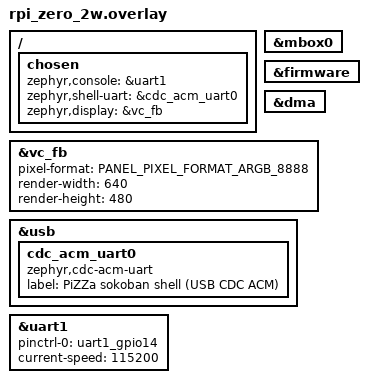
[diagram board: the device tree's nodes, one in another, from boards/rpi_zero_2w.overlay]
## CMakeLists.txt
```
# SPDX-License-Identifier: Apache-2.0
#
# PiZZa -- sokoban (howprice/sdl2-sokoban) via the shared SDL2 shim
# (apps/lib/sdl2shim).
#
# First consumer of the shim's SDL_Renderer engine + TTF-atlas + PIMG
# groups: the game is written against the renderer API proper (unlike
# Doom/SDLPoP/minivmac's app-side composition), so the lib owns the
# whole draw path and this app supplies only the diverging half --
# the baked asset pack + fd layer, the TMX loader over baked records,
# the present backend, the `sok` shell and the scripted timeline.
#
# The game tree is VENDORED at game/ (upstream is dormant; see
# game/PROVENANCE.md for the commit + local patches). MIT game, Apache
# shim/port glue.
#
# C++: the game is C++14-compatible C++; the proven aarch64 recipe is
# CONFIG_CPP + CONFIG_GLIBCXX_LIBCPP in prj.conf plus
# -DTOOLCHAIN_HAS_GLIBCXX=ON on the west line.

cmake_minimum_required(VERSION 3.20.0)

find_package(Zephyr REQUIRED HINTS $ENV{ZEPHYR_BASE})
project(pizza_sokoban LANGUAGES C CXX)

# sample_usbd helper for the USB CDC ACM shell, same as PizzaShell /
# Jet / wipeout / Doom / SDLPoP.
if(CONFIG_USB_DEVICE_STACK_NEXT)
  include(${ZEPHYR_BASE}/samples/subsys/usb/common/common.cmake)
endif()

set(SOK_GAME_DIR ${CMAKE_CURRENT_SOURCE_DIR}/game)

set(SOK_GAME_SRC
  ${SOK_GAME_DIR}/src/main.cpp
  ${SOK_GAME_DIR}/src/App.cpp
  ${SOK_GAME_DIR}/src/Game.cpp
  ${SOK_GAME_DIR}/src/MapRender.cpp
  ${SOK_GAME_DIR}/src/Renderer.cpp
  ${SOK_GAME_DIR}/src/TileMap.cpp
  ${SOK_GAME_DIR}/src/hp_assert.cpp
)

# ── shared shim (apps/lib/sdl2shim) ─────────────────────────────────
include(${CMAKE_CURRENT_SOURCE_DIR}/../lib/sdl2shim/sdl2shim.cmake)

set(SOK_SHIM_SRC
  src/shim_main.c
  src/shim_tmx.c
  src/sok_assets.c
  src/sok_pack.S
  ${SDL2SHIM_CORE_SOURCES}
  ${SDL2SHIM_SURFACE_SOURCES}
  ${SDL2SHIM_RW_SOURCES}
  ${SDL2SHIM_RENDER_SOURCES}
  ${SDL2SHIM_TTF_ATLAS_SOURCES}
  ${SDL2SHIM_IMAGE_PIMG_SOURCES}
)

# Audio backend (lib-owned): sokoban makes no audio calls at all, but
# the core's shim_stub.c delegates to the s2s_audio_* seam, so a
# backend TU must link. NONE stays correct even if a future game
# variant opens audio.
if(CONFIG_SDL2SHIM_AUDIO_HDMI)
  list(APPEND SOK_SHIM_SRC ${SDL2SHIM_AUDIO_HDMI_SOURCES})
else()
  list(APPEND SOK_SHIM_SRC ${SDL2SHIM_AUDIO_NONE})
endif()

# `sok` shell command set -- interactive key injection over USB CDC ACM.
if(CONFIG_SHELL)
  list(APPEND SOK_SHIM_SRC src/shim_shell.c)
endif()

# USB device stack bring-up (lib).
if(CONFIG_USB_DEVICE_STACK_NEXT)
  list(APPEND SOK_SHIM_SRC ${SDL2SHIM_USB})
endif()

# Frame present backend (app-local, as for every shim consumer).
if(CONFIG_SOKOBAN_PRESENT_DISPLAY)
  list(APPEND SOK_SHIM_SRC src/sok_present_display.c)
elseif(CONFIG_SOKOBAN_PRESENT_SEMIHOST)
  list(APPEND SOK_SHIM_SRC src/sok_present_semihost.c)
else()
  list(APPEND SOK_SHIM_SRC src/sok_present_none.c)
endif()

# Scripted synthetic input -- sokoban's title -> level 1 -> moves
# timeline for the qemu sim gate.
if(CONFIG_SOKOBAN_SCRIPTED_INPUT)
  list(APPEND SOK_SHIM_SRC src/shim_scripted.c)
endif()

# BT HID input (pad/keyboard/mouse) via apps/lib/btinput -- rpi_zero_2w
# only (boards/rpi_zero_2w.conf sets CONFIG_BTINPUT; qemu has no radio).
if(CONFIG_BTINPUT)
  include(${CMAKE_CURRENT_SOURCE_DIR}/../lib/btinput/btinput.cmake)
  # The BT patchram (.hcd) is a gitignored vendor blob (PROVENANCE.md).
  # Fail LOUDLY if missing: an empty-patchram image wedges the controller
  # at runtime (Download_Minidriver with nothing to launch).
  if(NOT CONFIG_AIROC_CUSTOM_FIRMWARE_HCD_BLOB)
    message(FATAL_ERROR
      "sokoban+BTINPUT: CONFIG_AIROC_CUSTOM_FIRMWARE_HCD_BLOB is unset")
  endif()
  set(_bt_blob "${CONFIG_AIROC_CUSTOM_FIRMWARE_HCD_BLOB}")
  if(NOT IS_ABSOLUTE "${_bt_blob}")
    set(_bt_blob "${CMAKE_CURRENT_SOURCE_DIR}/${_bt_blob}")
  endif()
  if(NOT EXISTS "${_bt_blob}")
    message(FATAL_ERROR
      "sokoban+BTINPUT: BT patchram not found:\n  ${_bt_blob}\n"
      "It is gitignored (vendor blob) -- fetch it per "
      "apps/lib/btinput/firmware/PROVENANCE.md before building.")
  endif()
  target_sources(app PRIVATE ${BTINPUT_SOURCES} src/sokoban_btinput.c)
  target_include_directories(app PRIVATE ${BTINPUT_INCLUDE_DIRS})
endif()

# Embedded asset pack: pack_assets.py bakes PNG -> PIMG, TMX -> S2TM
# and the ARCADE_N 8 px glyph atlas into one binary, linked via .incbin.
set(SOK_PACK_BIN ${CMAKE_BINARY_DIR}/sokoban_assets.bin)
file(GLOB_RECURSE SOK_DATA_FILES ${SOK_GAME_DIR}/data/*)
add_custom_command(
  OUTPUT ${SOK_PACK_BIN}
  COMMAND ${Python3_EXECUTABLE} ${CMAKE_CURRENT_SOURCE_DIR}/tools/pack_assets.py
          ${SOK_GAME_DIR}/data ${SOK_PACK_BIN} --font "Font/ARCADE_N.TTF@8"
  DEPENDS ${SOK_DATA_FILES}
          ${CMAKE_CURRENT_SOURCE_DIR}/tools/pack_assets.py
  COMMENT "Packing sokoban assets (PNG -> PIMG, TMX -> S2TM, TTF -> S2SA)"
)
add_custom_target(sok_assets_pack DEPENDS ${SOK_PACK_BIN})
add_dependencies(app sok_assets_pack)
set_source_files_properties(src/sok_pack.S PROPERTIES
  OBJECT_DEPENDS ${SOK_PACK_BIN}
  COMPILE_OPTIONS "-I${CMAKE_BINARY_DIR};-Wa,-I${CMAKE_BINARY_DIR}"
)

target_sources(app PRIVATE
  ${SOK_GAME_SRC}
  ${SOK_SHIM_SRC}
)

# include/ order: the shim's include/ first so <SDL2/SDL.h> resolves
# there; the game includes "SDL.h"/"SDL_ttf.h"/"tmx.h" unqualified, so
# the shim's SDL2/ subdir and this app's include/ (tmx.h) are on the
# path directly.
target_include_directories(app PRIVATE
  ${SDL2SHIM_INCLUDE_DIRS}
  ${SDL2SHIM_DIR}/include/SDL2
  include
  src
)

# The vendored game trips warnings its desktop builds silence.
set_source_files_properties(${SOK_GAME_SRC} PROPERTIES COMPILE_OPTIONS
  "-Wno-unused-variable;-Wno-unused-but-set-variable;-Wno-unused-parameter;-Wno-missing-field-initializers;-Wno-format-truncation;-Wno-double-promotion"
)
```

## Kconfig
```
# SPDX-License-Identifier: Apache-2.0
#
# PiZZa sokoban port -- app options.

# SAMPLE_USBD_* options for sample_usbd_init.c on boards with the USB
# device stack. Same pattern PizzaShell / Jet / wipeout / SDLPoP use.
source "samples/subsys/usb/common/Kconfig.sample_usbd"

# Shared shim: the audio-backend choice (NONE default -- sokoban makes
# no audio calls) and the SDL2SHIM log module live here.
rsource "../lib/sdl2shim/Kconfig"
# BT HID input (pad/keyboard/mouse) -- enabled per-board (rpi_zero_2w).
rsource "../lib/btinput/Kconfig"

menu "PiZZa sokoban port"

choice SOKOBAN_PRESENT_BACKEND
	prompt "Frame present backend"
	default SOKOBAN_PRESENT_DISPLAY if DISPLAY
	default SOKOBAN_PRESENT_NONE

config SOKOBAN_PRESENT_DISPLAY
	bool "Zephyr display API (bcm2835_fb + HVS scaling on hardware)"
	depends on DISPLAY

config SOKOBAN_PRESENT_NONE
	bool "Drop frames (link/sim bring-up)"

config SOKOBAN_PRESENT_SEMIHOST
	bool "Semihosting PPM capture (qemu sim gates)"
	depends on SEMIHOST

endchoice

config SOKOBAN_CAPTURE_EVERY
	int "Capture every Nth presented frame (0 = first frame only)"
	depends on SOKOBAN_PRESENT_SEMIHOST
	default 0

config SOKOBAN_SCRIPTED_INPUT
	bool "Drive the game from the scripted synthetic input timeline"
	default n

module = SOKOBAN
module-str = sokoban
source "subsys/logging/Kconfig.template.log_config"

endmenu

source "Kconfig.zephyr"
```

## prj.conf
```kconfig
# SPDX-License-Identifier: Apache-2.0
#
# Common config for the PiZZa sokoban port. Per-board overrides
# (display, USB, semihost capture) live in boards/<board>.conf.

CONFIG_PRINTK=y
CONFIG_BOOT_BANNER=y

# Keep printk() synchronous so boot-time logging lands on the console
# even when the render loop is busy (Jet/wipeout pattern).
CONFIG_LOG_PRINTK=n

# picolibc's errno needs TLS -- same hard-won stanza as the wipeout /
# SDLPoP ports.
CONFIG_TOOLCHAIN_CROSS_COMPILE_SUPPORTS_THREAD_LOCAL_STORAGE=y
CONFIG_THREAD_LOCAL_STORAGE=y

# C++ game sources: the proven aarch64 recipe (real libstdc++ from the
# SDK; needs -DTOOLCHAIN_HAS_GLIBCXX=ON on the west line). No
# exceptions/RTTI -- the game uses neither.
CONFIG_CPP=y
CONFIG_STD_CPP17=y
CONFIG_GLIBCXX_LIBCPP=y

# Heap: the renderer's 640x480 ARGB backing (1.2 MB), the per-level
# map texture (level maps up to ~720x468 -> ~1.4 MB), tileset texture
# + text surfaces, and the ~2.3 MB Game object (new'd). 8 MiB is
# generous headroom.
CONFIG_COMMON_LIBC_MALLOC_ARENA_SIZE=8388608

# The game runs on the Zephyr main thread.
CONFIG_MAIN_STACK_SIZE=65536

CONFIG_FPU=y
CONFIG_STACK_SENTINEL=y
CONFIG_ASSERT=y

# Audio: sokoban makes no SDL audio / Mix_* calls at all; the shim's
# AUDIO_NONE backend (Kconfig default) is the correct choice on every
# board -- do not wire the HDMI backend "for symmetry".
```

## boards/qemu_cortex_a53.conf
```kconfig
# SPDX-License-Identifier: Apache-2.0
#
# qemu_cortex_a53 -- the SIM target. No display hardware: frames leave
# the guest as PPM files via semihosting (sok_present_semihost.c); the
# scripted timeline drives title -> level 1 -> UP/LEFT/LEFT.

# Run the emulated CPU at wall speed (same rationale as SDLPoP: the
# default -icount stretches software rendering ~40x in wall-clock).
CONFIG_QEMU_ICOUNT=n

CONFIG_SEMIHOST=y
CONFIG_SOKOBAN_PRESENT_SEMIHOST=y
CONFIG_SOKOBAN_CAPTURE_EVERY=40
CONFIG_SOKOBAN_SCRIPTED_INPUT=y

# Synchronous shim logging on the emulated console.
CONFIG_LOG=y
CONFIG_LOG_MODE_MINIMAL=y
CONFIG_SOKOBAN_LOG_LEVEL_DBG=y
```

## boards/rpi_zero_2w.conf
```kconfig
# SPDX-License-Identifier: Apache-2.0
#
# Raspberry Pi Zero 2 W (BCM2710, Cortex-A53, AArch64) -- sokoban.
# Console + logs on the mini-UART, interactive shell (`sok key ...`)
# on USB CDC ACM, HDMI via the VC firmware framebuffer with HVS
# 640x480 scaling. No audio (the game makes no audio calls).

CONFIG_BOOT_DELAY=200

# VC mailbox + firmware (framebuffer alloc chain).
CONFIG_RASPBERRYPI_FIRMWARE=y

# HDMI display via VC firmware FB, ARGB_8888. The renderer's 640x480
# frame lands in the virtual FB; HVS scales to the monitor's native
# mode.
CONFIG_DISPLAY=y
CONFIG_BCM2835_FB=y

# BCM2835 DMA -- FB driver claims a channel for the backbuffer blit.
CONFIG_DMA=y
CONFIG_DMA_BCM2835=y

# USB CDC ACM shell, same shape as PizzaShell / wipeout / SDLPoP.
CONFIG_USB_DEVICE_STACK_NEXT=y
CONFIG_UDC_DWC2=y
CONFIG_UDC_DWC2_DMA=n
CONFIG_SERIAL=y
CONFIG_USBD_CDC_ACM_CLASS=y
CONFIG_CDC_ACM_SERIAL_INITIALIZE_AT_BOOT=n
CONFIG_SAMPLE_USBD_PRODUCT="PiZZa sokoban -- rpi_zero_2w"
CONFIG_SAMPLE_USBD_MANUFACTURER="jetpax/PiZZa"
CONFIG_SAMPLE_USBD_PID=0xCAFE
CONFIG_USBD_THREAD_STACK_SIZE=4096
CONFIG_UDC_DWC2_STACK_SIZE=4096

CONFIG_SHELL=y
CONFIG_SHELL_BACKEND_SERIAL=y
CONFIG_KERNEL_SHELL=y
CONFIG_SHELL_STACK_SIZE=8192
CONFIG_SHELL_VT100_COMMANDS=y
CONFIG_SHELL_HISTORY=y
CONFIG_SHELL_TAB=y
CONFIG_SHELL_LOG_BACKEND=n

# Logging on the board console (mini-UART), off the shell prompt.
CONFIG_LOG=y
CONFIG_LOG_BUFFER_SIZE=16384
CONFIG_LOG_BACKEND_UART=y
CONFIG_LOG_MODE_DEFERRED=y
CONFIG_USBD_CDC_ACM_LOG_LEVEL_WRN=y
CONFIG_USBD_LOG_LEVEL_INF=y
CONFIG_UDC_DRIVER_LOG_LEVEL_WRN=y

# ── Bluetooth HID input (8BitDo pad -> sokoban keys) ─────────────────
# Stack, host profile and connection policy all live in apps/lib/btinput;
# config mirrors the HW-proven minivmac/DOSBox bring-up. The pad keymap
# (K-mode letters -> arrows/O/M/R/U/space) is in sokoban_btinput.c.
CONFIG_BTINPUT=y
CONFIG_BTINPUT_HOGP=y
CONFIG_BTINPUT_SEAM_SDL=y
CONFIG_BTINPUT_MANAGER=y

CONFIG_BT=y
CONFIG_BT_CLASSIC=y
CONFIG_BT_DEVICE_NAME="PiZZa"
CONFIG_BT_MAX_PAIRED=8
CONFIG_BT_MAX_CONN=3
# The 8BitDo's fw is legacy-only SMP; Just Works is the accepted trust model.
CONFIG_BT_SMP_SC_PAIR_ONLY=n
# The 4.2 controller has 1M PHY only; skip the doomed LE Set PHY attempt.
CONFIG_BT_AUTO_PHY_UPDATE=n

# Infineon AIROC patchram: this unit is the Synaptics 43436S module
# (BT ROM = 43430A1). Blob is gitignored; PROVENANCE.md has the fetch.
CONFIG_BT_AIROC=y
CONFIG_BT_AIROC_CUSTOM=y
CONFIG_AIROC_CUSTOM_FIRMWARE_HCD_BLOB="../lib/btinput/firmware/SYN43430A1.hcd"

# Bond persistence: settings FILE backend on the SD FAT (the manager
# mounts /SD:). MKFS stays off -- the card is PiZZa-imaged.
CONFIG_BT_SETTINGS=y
CONFIG_SETTINGS=y
CONFIG_SETTINGS_FILE=y
CONFIG_SETTINGS_FILE_PATH="/SD:/bt/settings"
CONFIG_DISK_ACCESS=y
CONFIG_DISK_DRIVERS=y
CONFIG_SDMMC_SUBSYS=y
CONFIG_FILE_SYSTEM=y
CONFIG_FAT_FILESYSTEM_ELM=y
CONFIG_FS_FATFS_LFN=y
CONFIG_FILE_SYSTEM_MKFS=n
# FS_FATFS_MOUNT_MKFS defaults Y and would REFORMAT (wipe) the SD on
# any mount failure -- the minivmac Phase-6 near-miss. Force it off.
CONFIG_FS_FATFS_MOUNT_MKFS=n

# ELM FatFs is NOT thread-safe by default; the bond store alone has two
# FatFs users (btinput manager thread + system workqueue for settings
# saves). Same fix as minivmac: per-volume mutex + LFN buffer on stack.
CONFIG_FS_FATFS_REENTRANT=y
CONFIG_FS_FATFS_LFN_MODE_STACK=y

# aarch64: BT stack defaults are Cortex-M sized; P-256 on the long WQ
# needs 8K frames (instruction-abort class otherwise).
CONFIG_BT_LONG_WQ_STACK_SIZE=8192
CONFIG_BT_RX_STACK_SIZE=8192
CONFIG_BT_HCI_TX_STACK_SIZE_WITH_PROMPT=y
CONFIG_BT_HCI_TX_STACK_SIZE=4096
CONFIG_SYSTEM_WORKQUEUE_STACK_SIZE=8192
CONFIG_THREAD_NAME=y

# Bond hygiene (HW-proven on minivmac): let a re-pairing peer whose new
# IRK resolves an existing bond replace it instead of being refused, and
# allow JW-over-JW overwrites (JW has no MITM protection anyway).
CONFIG_BT_ID_UNPAIR_MATCHING_BONDS=y
CONFIG_BT_SMP_ALLOW_UNAUTH_OVERWRITE=y
```

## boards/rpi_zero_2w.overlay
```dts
/*
 * SPDX-License-Identifier: Apache-2.0
 *
 * PiZZa sokoban overlay for rpi_zero_2w.
 *
 *   - &mbox0 + &firmware: VC mailbox + property tags (FB alloc).
 *   - &vc_fb: HDMI framebuffer at the monitor's EDID-negotiated
 *     scanout mode; the renderer paints its native 640x480 frame into
 *     the virtual FB and the VideoCore HVS scales it to the cable on
 *     the fly -- the proven Jet / wipeout / Doom / SDLPoP trick.
 *     640 * 4 = 2560 bytes/row = 64-byte aligned, so the FB driver's
 *     contiguous-DMA fast path engages.
 *   - &dma: BCM2835 DMA for the backbuffer->fb blit.
 *   - &usb + cdc_acm child: USB CDC ACM shell endpoint.
 *   - mini-UART (uart1) console + LOG target, PiZZa convention.
 */

#include <zephyr/dt-bindings/display/panel.h>

&mbox0 {
	status = "okay";
};

&firmware {
	status = "okay";
};

&dma {
	status = "okay";
};

&vc_fb {
	pixel-format = <PANEL_PIXEL_FORMAT_ARGB_8888>;
	render-width = <640>;
	render-height = <480>;
	status = "okay";
};

&usb {
	status = "okay";

	cdc_acm_uart0: cdc_acm_uart0 {
		compatible = "zephyr,cdc-acm-uart";
		label = "PiZZa sokoban shell (USB CDC ACM)";
	};
};

/ {
	chosen {
		zephyr,console = &uart1;
		zephyr,shell-uart = &cdc_acm_uart0;
		zephyr,display = &vc_fb;
	};
};

&uart1 {
	pinctrl-names = "default";
	pinctrl-0 = <&uart1_gpio14>;
	status = "okay";
	current-speed = <115200>;
};
```

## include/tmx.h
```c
/*
 * SPDX-License-Identifier: Apache-2.0
 *
 * PiZZa sokoban port -- libtmx API subset over baked S2TM records.
 *
 * sdl2-sokoban loads its Tiled maps through baylej/tmx (libxml2 +
 * zlib). On the device the maps are pre-baked at build time
 * (tools/pack_assets.py) into compact S2TM records, and this header +
 * shim_tmx.c reimplement exactly the slice of the libtmx API the game
 * walks: one tile layer of gids, one object group of tile objects,
 * one tileset, tmx_get_tile. Member names and types mirror upstream
 * libtmx so the game sources compile unmodified.
 */

#ifndef PIZZA_SOKOBAN_TMX_H
#define PIZZA_SOKOBAN_TMX_H

#include <stdint.h>

#ifdef __cplusplus
extern "C" {
#endif

#define TMX_FLIP_BITS_REMOVAL 0x1FFFFFFFu

enum tmx_layer_type {
	L_NONE,
	L_LAYER,
	L_OBJGR,
	L_IMAGE,
};

enum tmx_obj_type {
	OT_NONE,
	OT_SQUARE,
	OT_POLYGON,
	OT_POLYLINE,
	OT_ELLIPSE,
	OT_TILE,
};

typedef struct tmx_image {
	char *source;
	void *resource_image;   /* SDL_Surface* via tmx_img_load_func */
} tmx_image;

typedef struct tmx_shape {
	double **points;
	int points_len;
} tmx_shape;

typedef struct tmx_object {
	int visible;
	enum tmx_obj_type obj_type;
	double x, y;
	double width, height;
	union {
		int gid;
		tmx_shape *shape;
	} content;
	struct tmx_object *next;
} tmx_object;

typedef struct tmx_object_group {
	unsigned int color;
	tmx_object *head;
} tmx_object_group;

typedef struct tmx_tileset {
	unsigned int tile_width;
	unsigned int tile_height;
	tmx_image *image;
} tmx_tileset;

typedef struct tmx_tileset_list {
	unsigned int firstgid;
	tmx_tileset *tileset;
	struct tmx_tileset_list *next;
} tmx_tileset_list;

typedef struct tmx_tile {
	unsigned int id;
	tmx_tileset *tileset;
	unsigned int ul_x;
	unsigned int ul_y;
} tmx_tile;

typedef struct tmx_layer {
	int visible;
	double opacity;
	enum tmx_layer_type type;
	union {
		uint32_t *gids;
		tmx_object_group *objgr;
		tmx_image *image;
	} content;
	struct tmx_layer *next;
} tmx_layer;

typedef struct tmx_map {
	unsigned int width;
	unsigned int height;
	unsigned int tile_width;
	unsigned int tile_height;
	int backgroundcolor;    /* 0xRRGGBB */
	tmx_layer *ly_head;
	tmx_tileset_list *ts_head;
} tmx_map;

tmx_map *tmx_load(const char *path);
void tmx_map_free(tmx_map *map);
tmx_tile *tmx_get_tile(tmx_map *map, unsigned int gid);
void tmx_perror(const char *prefix);

extern void *(*tmx_img_load_func)(const char *path);
extern void (*tmx_img_free_func)(void *address);

#ifdef __cplusplus
}
#endif

#endif /* PIZZA_SOKOBAN_TMX_H */
```

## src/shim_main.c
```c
/*
 * SPDX-License-Identifier: Apache-2.0
 *
 * PiZZa sokoban port -- Zephyr entry point.
 *
 * The game's own main() is renamed to SDL_main by the shim's SDL.h
 * (standard SDL trick); the Zephyr main thread becomes the game
 * thread. The game only returns on ESC/quit.
 */

#include <zephyr/kernel.h>
#include <stdio.h>

#include "sdl2shim.h"

#ifdef CONFIG_BTINPUT
void sokoban_btinput_start(void);
#endif

int main(void)
{
	static char *argv[] = { "sokoban", NULL };

	printf("[sokoban] PiZZa sokoban port, board %s\n", CONFIG_BOARD);

	if (IS_ENABLED(CONFIG_SOKOBAN_SCRIPTED_INPUT)) {
		s2s_scripted_input_start();
	}

#ifdef CONFIG_BTINPUT
	sokoban_btinput_start();
#endif

	/* The game quits on ESC, but an appliance has nothing to exit to --
	 * relaunch at the title screen instead. App::ShutDown tears the
	 * renderer/window down cleanly, so a fresh SDL_main re-creates them.
	 */
	for (;;) {
		int rc = SDL_main(1, argv);

		printf("[sokoban] game exited: %d -- relaunching\n", rc);
		k_msleep(1000);
	}
	return 0;
}
```

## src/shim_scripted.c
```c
/*
 * SPDX-License-Identifier: Apache-2.0
 *
 * PiZZa sokoban -- scripted synthetic input (CONFIG_SOKOBAN_SCRIPTED_INPUT).
 *
 * Drives the sim gate on qemu: hold on the title screen (frames
 * captured), press O to start the Original levels, then walk the only
 * legal opening of level 1 -- the man starts at tile (11,8) walled
 * left/right/down, so UP, then LEFT twice along the open corridor.
 * Each press is a KEYDOWN, a hold long enough to span a frame, and a
 * KEYUP; the game latches held keys once per frame and a started move
 * completes on its own.
 */

#include <zephyr/kernel.h>

#include "sdl2shim.h"

#define SCRIPT_STACK_SIZE 2048

static K_THREAD_STACK_DEFINE(script_stack, SCRIPT_STACK_SIZE);
static struct k_thread script_thread;

static void press(SDL_Scancode sc, int hold_ms)
{
	SDL_Event ev = { 0 };

	ev.type = SDL_KEYDOWN;
	ev.key.state = SDL_PRESSED;
	ev.key.keysym.scancode = sc;
	s2s_event_submit(&ev);

	k_msleep(hold_ms);

	ev.type = SDL_KEYUP;
	ev.key.state = SDL_RELEASED;
	s2s_event_submit(&ev);
}

static void script_run(void *a, void *b, void *c)
{
	ARG_UNUSED(a);
	ARG_UNUSED(b);
	ARG_UNUSED(c);

	/* title screen renders + gets captured */
	k_msleep(3000);
	press(SDL_SCANCODE_O, 150);

	/* level 1 loads + renders */
	k_msleep(2000);
	press(SDL_SCANCODE_UP, 150);
	k_msleep(1500);
	press(SDL_SCANCODE_LEFT, 150);
	k_msleep(1500);
	press(SDL_SCANCODE_LEFT, 150);

	/* final state renders + gets captured */
	k_msleep(3000);
	printk("[sokoban] scripted input done\n");
}

void s2s_scripted_input_start(void)
{
	k_thread_create(&script_thread, script_stack, SCRIPT_STACK_SIZE,
			script_run, NULL, NULL, NULL,
			K_PRIO_PREEMPT(8), 0, K_NO_WAIT);
	k_thread_name_set(&script_thread, "sok_script");
}
```

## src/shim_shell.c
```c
/*
 * SPDX-License-Identifier: Apache-2.0
 *
 * PiZZa sokoban -- `sok` shell command set (USB CDC ACM).
 *
 * Interactive key injection: the input path on hardware until a HOGP
 * keyboard lands (the shim event seam already accepts any producer).
 * `sok key <name> [hold_ms]` submits KEYDOWN, holds on a one-shot
 * timer, then submits KEYUP -- the game latches held keys once per
 * frame, so the default hold spans several frames and a started move
 * completes on its own.
 */

#include <zephyr/kernel.h>
#include <zephyr/shell/shell.h>
#include <stdlib.h>
#include <string.h>

#include "sdl2shim.h"

#define SOK_DEFAULT_HOLD_MS 150

static struct k_timer keyup_timer;
static SDL_Scancode held_sc;

static const struct {
	const char *name;
	SDL_Scancode sc;
} key_map[] = {
	{ "up", SDL_SCANCODE_UP },
	{ "down", SDL_SCANCODE_DOWN },
	{ "left", SDL_SCANCODE_LEFT },
	{ "right", SDL_SCANCODE_RIGHT },
	{ "o", SDL_SCANCODE_O },
	{ "m", SDL_SCANCODE_M },
	{ "p", SDL_SCANCODE_P },
	{ "r", SDL_SCANCODE_R },
	{ "u", SDL_SCANCODE_U },
	{ "space", SDL_SCANCODE_SPACE },
	{ "esc", SDL_SCANCODE_ESCAPE },
};

static void submit_key(SDL_Scancode sc, Uint32 type)
{
	SDL_Event ev = { 0 };

	ev.type = type;
	ev.key.state = (type == SDL_KEYDOWN) ? SDL_PRESSED : SDL_RELEASED;
	ev.key.keysym.scancode = sc;
	s2s_event_submit(&ev);
}

static void keyup_expiry(struct k_timer *timer)
{
	ARG_UNUSED(timer);
	submit_key(held_sc, SDL_KEYUP);
}

static int cmd_sok_key(const struct shell *sh, size_t argc, char **argv)
{
	int hold_ms = SOK_DEFAULT_HOLD_MS;

	if (argc >= 3) {
		hold_ms = atoi(argv[2]);
		if (hold_ms < 10 || hold_ms > 5000) {
			shell_error(sh, "hold_ms out of range (10..5000)");
			return -EINVAL;
		}
	}

	for (size_t i = 0; i < ARRAY_SIZE(key_map); i++) {
		if (strcmp(argv[1], key_map[i].name) == 0) {
			if (k_timer_remaining_get(&keyup_timer) > 0) {
				/* release the previous key first */
				k_timer_stop(&keyup_timer);
				submit_key(held_sc, SDL_KEYUP);
			}
			held_sc = key_map[i].sc;
			submit_key(held_sc, SDL_KEYDOWN);
			k_timer_start(&keyup_timer, K_MSEC(hold_ms), K_NO_WAIT);
			return 0;
		}
	}

	shell_error(sh, "unknown key '%s'", argv[1]);
	shell_print(sh, "keys: up down left right o m p r u space esc");
	return -EINVAL;
}

static int sok_shell_init(void)
{
	k_timer_init(&keyup_timer, keyup_expiry, NULL);
	return 0;
}

SYS_INIT(sok_shell_init, APPLICATION, CONFIG_APPLICATION_INIT_PRIORITY);

SHELL_STATIC_SUBCMD_SET_CREATE(sub_sok,
	SHELL_CMD_ARG(key, NULL,
		      "inject a key press: sok key <name> [hold_ms]",
		      cmd_sok_key, 2, 1),
	SHELL_SUBCMD_SET_END);

SHELL_CMD_REGISTER(sok, &sub_sok, "sokoban controls", NULL);
```

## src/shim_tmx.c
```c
/*
 * SPDX-License-Identifier: Apache-2.0
 *
 * PiZZa sokoban port -- tmx_load over baked S2TM records.
 *
 * tools/pack_assets.py pre-parses each Tiled .tmx (XML + base64/zlib)
 * into an S2TM record at build time; loading a map on the device is a
 * header parse + struct build. The gid grid is used in place (it
 * points into the read-only pack); everything else is malloc'd and
 * freed by tmx_map_free.
 *
 * S2TM layout (LE, packed), mirrored by the baker:
 *   u8  magic[4] "S2TM"
 *   u16 width, height, tile_w, tile_h
 *   u32 backgroundcolor (0xRRGGBB)
 *   u16 nobjects, firstgid, tile_count, columns
 *   char image[64]                        pack key of the tileset image
 *   u32 gids[width*height]                flip bits preserved
 *   { u32 gid; i32 x, y, w, h; }[nobjects]
 *
 * Dual-target: builds under Zephyr and in the host pack test.
 */

#include <stdlib.h>
#include <string.h>
#include <stdio.h>

#include "s2s_compat.h"
#include "sdl2shim.h"
#include <tmx.h>

void *(*tmx_img_load_func)(const char *path);
void (*tmx_img_free_func)(void *address);

struct s2tm_header {
	uint8_t magic[4];
	uint16_t width, height;
	uint16_t tile_w, tile_h;
	uint32_t backgroundcolor;
	uint16_t nobjects;
	uint16_t firstgid;
	uint16_t tile_count;
	uint16_t columns;
	char image[64];
} __packed;

struct s2tm_obj {
	uint32_t gid;
	int32_t x, y, w, h;
} __packed;

/* One allocation carries every fixed-size piece; the object list and
 * tile table are sized per map.
 */
struct s2tm_runtime {
	tmx_map map;
	tmx_layer tile_layer;
	tmx_layer obj_layer;
	tmx_object_group objgr;
	tmx_tileset_list ts_list;
	tmx_tileset tileset;
	tmx_image image;
	tmx_object *objects;
	tmx_tile *tiles;
	unsigned int tile_count;
};

tmx_map *tmx_load(const char *path)
{
	size_t size;
	const uint8_t *blob = s2s_asset_find(path, &size);

	if (blob == NULL) {
		s2s_set_error("tmx_load: %s not in asset pack", path);
		return NULL;
	}

	const struct s2tm_header *hdr = (const struct s2tm_header *)blob;

	if (size < sizeof(*hdr) || memcmp(hdr->magic, "S2TM", 4) != 0) {
		s2s_set_error("tmx_load: %s is not an S2TM record", path);
		return NULL;
	}

	size_t ntiles_grid = (size_t)hdr->width * hdr->height;
	size_t need = sizeof(*hdr) + ntiles_grid * 4 +
		      (size_t)hdr->nobjects * sizeof(struct s2tm_obj);

	if (size < need) {
		s2s_set_error("tmx_load: %s truncated (%zu < %zu)", path, size, need);
		return NULL;
	}

	struct s2tm_runtime *rt = calloc(1, sizeof(*rt));

	if (rt == NULL) {
		s2s_set_error("tmx_load: out of memory");
		return NULL;
	}
	rt->objects = calloc(hdr->nobjects ? hdr->nobjects : 1, sizeof(tmx_object));
	rt->tiles = calloc(hdr->tile_count ? hdr->tile_count : 1, sizeof(tmx_tile));
	if (rt->objects == NULL || rt->tiles == NULL) {
		free(rt->objects);
		free(rt->tiles);
		free(rt);
		s2s_set_error("tmx_load: out of memory");
		return NULL;
	}

	rt->map.width = hdr->width;
	rt->map.height = hdr->height;
	rt->map.tile_width = hdr->tile_w;
	rt->map.tile_height = hdr->tile_h;
	rt->map.backgroundcolor = (int)hdr->backgroundcolor;

	/* tileset + per-gid tile table (ul_x/ul_y from the column grid) */
	rt->tileset.tile_width = hdr->tile_w;
	rt->tileset.tile_height = hdr->tile_h;
	rt->tileset.image = &rt->image;
	rt->ts_list.firstgid = hdr->firstgid;
	rt->ts_list.tileset = &rt->tileset;
	rt->map.ts_head = &rt->ts_list;
	rt->tile_count = hdr->tile_count;

	for (unsigned int i = 0; i < hdr->tile_count; i++) {
		rt->tiles[i].id = i;
		rt->tiles[i].tileset = &rt->tileset;
		rt->tiles[i].ul_x = (i % hdr->columns) * hdr->tile_w;
		rt->tiles[i].ul_y = (i / hdr->columns) * hdr->tile_h;
	}

	/* the tile layer's gid grid lives in the (aligned) pack blob */
	rt->tile_layer.visible = 1;
	rt->tile_layer.opacity = 1.0;
	rt->tile_layer.type = L_LAYER;
	rt->tile_layer.content.gids = (uint32_t *)(blob + sizeof(*hdr));
	rt->tile_layer.next = &rt->obj_layer;

	const struct s2tm_obj *objs =
		(const struct s2tm_obj *)(blob + sizeof(*hdr) + ntiles_grid * 4);

	for (unsigned int i = 0; i < hdr->nobjects; i++) {
		tmx_object *o = &rt->objects[i];

		o->visible = 1;
		o->obj_type = OT_TILE;
		o->x = objs[i].x;
		o->y = objs[i].y;
		o->width = objs[i].w;
		o->height = objs[i].h;
		o->content.gid = (int)objs[i].gid;
		o->next = (i + 1 < hdr->nobjects) ? &rt->objects[i + 1] : NULL;
	}
	rt->objgr.color = 0;
	rt->objgr.head = hdr->nobjects ? &rt->objects[0] : NULL;

	rt->obj_layer.visible = 1;
	rt->obj_layer.opacity = 1.0;
	rt->obj_layer.type = L_OBJGR;
	rt->obj_layer.content.objgr = &rt->objgr;
	rt->obj_layer.next = NULL;

	rt->map.ly_head = &rt->tile_layer;

	if (tmx_img_load_func != NULL) {
		rt->image.resource_image = tmx_img_load_func(hdr->image);
		if (rt->image.resource_image == NULL) {
			s2s_set_error("tmx_load: tileset image '%s' failed", hdr->image);
			tmx_map_free(&rt->map);
			return NULL;
		}
	}

	return &rt->map;
}

void tmx_map_free(tmx_map *map)
{
	if (map == NULL) {
		return;
	}

	struct s2tm_runtime *rt = (struct s2tm_runtime *)map;

	if (rt->image.resource_image != NULL && tmx_img_free_func != NULL) {
		tmx_img_free_func(rt->image.resource_image);
	}
	free(rt->objects);
	free(rt->tiles);
	free(rt);
}

tmx_tile *tmx_get_tile(tmx_map *map, unsigned int gid)
{
	struct s2tm_runtime *rt = (struct s2tm_runtime *)map;

	gid &= TMX_FLIP_BITS_REMOVAL;
	if (gid < rt->ts_list.firstgid) {
		return NULL;
	}

	unsigned int id = gid - rt->ts_list.firstgid;

	if (id >= rt->tile_count) {
		return NULL;
	}
	return &rt->tiles[id];
}

void tmx_perror(const char *prefix)
{
	fprintf(stderr, "%s: %s\n", prefix, SDL_GetError());
}
```

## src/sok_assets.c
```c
/*
 * SPDX-License-Identifier: Apache-2.0
 *
 * PiZZa sokoban port -- embedded asset store.
 *
 * The pack built by tools/pack_assets.py is linked into .rodata; this
 * file implements the read-only POSIX fd layer over it (picolibc's
 * tinystdio funnels fopen/fread through open/read), plus the direct
 * s2s_asset_find lookup the shim's IMG/TTF/TMX loaders use. Same
 * recipe as SDLPoP's pop_assets.c; sokoban asks for pack-root-relative
 * paths ("Font/ARCADE_N.TTF", "Maps/Original/level_001.tmx") so the
 * exe-dir retry heuristics are gone.
 *
 * The game only opens files to probe level existence (fopen/fclose in
 * InitLevel); writes fail EROFS.
 */

#include <zephyr/kernel.h>
#include <zephyr/sys/printk.h>
#include <errno.h>
#include <fcntl.h>
#include <stdlib.h>
#include <string.h>
#include <sys/stat.h>
#include <sys/types.h>
#include <unistd.h>

struct pack_entry {
	uint32_t path_off;
	uint32_t data_off;
	uint32_t size;
} __packed;

extern const uint8_t sok_pack_start[];
extern const uint8_t sok_pack_end[];

static const struct pack_entry *pack_entries;
static uint32_t pack_count;
static bool pack_ready;

#define SOK_FD_BASE 3
#define SOK_FD_MAX  8

static struct {
	const struct pack_entry *entry;
	size_t pos;
	bool used;
} fds[SOK_FD_MAX];

static void pack_init(void)
{
	if (pack_ready) {
		return;
	}
	if (memcmp(sok_pack_start, "SOKPACK1", 8) != 0) {
		printk("[sokoban] asset pack magic mismatch!\n");
		pack_count = 0;
	} else {
		pack_count = *(const uint32_t *)(sok_pack_start + 8);
		pack_entries = (const struct pack_entry *)(sok_pack_start + 12);
		printk("[sokoban] asset pack: %u entries, %u bytes\n",
		       pack_count, (uint32_t)(sok_pack_end - sok_pack_start));
	}
	pack_ready = true;
}

static const char *entry_path(const struct pack_entry *e)
{
	return (const char *)sok_pack_start + e->path_off;
}

static const struct pack_entry *pack_lookup(const char *path)
{
	pack_init();
	if (path == NULL || pack_count == 0) {
		return NULL;
	}

	while (path[0] == '.' && path[1] == '/') {
		path += 2;
	}
	while (path[0] == '/') {
		path++;
	}

	uint32_t lo = 0, hi = pack_count;

	while (lo < hi) {
		uint32_t mid = (lo + hi) / 2;
		int c = strcmp(entry_path(&pack_entries[mid]), path);

		if (c == 0) {
			return &pack_entries[mid];
		}
		if (c < 0) {
			lo = mid + 1;
		} else {
			hi = mid;
		}
	}
	return NULL;
}

/* ── POSIX fd layer (picolibc tinystdio backend) ─────────────── */

int open(const char *path, int flags, ...)
{
	if ((flags & O_ACCMODE) != O_RDONLY) {
		errno = EROFS;
		return -1;
	}

	const struct pack_entry *e = pack_lookup(path);

	if (e == NULL) {
		errno = ENOENT;
		return -1;
	}

	for (int i = 0; i < SOK_FD_MAX; i++) {
		if (!fds[i].used) {
			fds[i].entry = e;
			fds[i].pos = 0;
			fds[i].used = true;
			return SOK_FD_BASE + i;
		}
	}
	errno = EMFILE;
	return -1;
}

static int fd_slot(int fd)
{
	int i = fd - SOK_FD_BASE;

	if (i < 0 || i >= SOK_FD_MAX || !fds[i].used) {
		return -1;
	}
	return i;
}

int close(int fd)
{
	int i = fd_slot(fd);

	if (i < 0) {
		errno = EBADF;
		return -1;
	}
	fds[i].used = false;
	return 0;
}

ssize_t read(int fd, void *buf, size_t count)
{
	int i = fd_slot(fd);

	if (i < 0) {
		errno = EBADF;
		return -1;
	}

	const struct pack_entry *e = fds[i].entry;
	size_t avail = e->size - fds[i].pos;
	size_t n = MIN(count, avail);

	memcpy(buf, sok_pack_start + e->data_off + fds[i].pos, n);
	fds[i].pos += n;
	return (ssize_t)n;
}

ssize_t write(int fd, const void *buf, size_t count)
{
	ARG_UNUSED(buf);
	ARG_UNUSED(count);
	errno = (fd_slot(fd) < 0) ? EBADF : EROFS;
	return -1;
}

off_t lseek(int fd, off_t offset, int whence)
{
	int i = fd_slot(fd);

	if (i < 0) {
		errno = EBADF;
		return (off_t)-1;
	}

	const struct pack_entry *e = fds[i].entry;
	off_t base;

	switch (whence) {
	case SEEK_SET:
		base = 0;
		break;
	case SEEK_CUR:
		base = (off_t)fds[i].pos;
		break;
	case SEEK_END:
		base = (off_t)e->size;
		break;
	default:
		errno = EINVAL;
		return (off_t)-1;
	}

	off_t target = base + offset;

	if (target < 0 || target > (off_t)e->size) {
		errno = EINVAL;
		return (off_t)-1;
	}
	fds[i].pos = (size_t)target;
	return target;
}

int fstat(int fd, struct stat *st)
{
	int i = fd_slot(fd);

	if (i < 0) {
		errno = EBADF;
		return -1;
	}
	memset(st, 0, sizeof(*st));
	st->st_size = (off_t)fds[i].entry->size;
	st->st_mode = S_IFREG | 0444;
	return 0;
}

int stat(const char *path, struct stat *st)
{
	const struct pack_entry *e = pack_lookup(path);

	if (e == NULL) {
		errno = ENOENT;
		return -1;
	}
	memset(st, 0, sizeof(*st));
	st->st_size = (off_t)e->size;
	st->st_mode = S_IFREG | 0444;
	return 0;
}

int access(const char *path, int mode)
{
	if (pack_lookup(path) == NULL) {
		errno = ENOENT;
		return -1;
	}
	if ((mode & W_OK) != 0) {
		errno = EROFS;
		return -1;
	}
	return 0;
}

/* Direct lookup for shim-internal users (IMG_Load, TTF_OpenFont,
 * tmx_load).
 */
const void *s2s_asset_find(const char *path, size_t *size)
{
	const struct pack_entry *e = pack_lookup(path);

	if (e == NULL) {
		return NULL;
	}
	if (size != NULL) {
		*size = e->size;
	}
	return sok_pack_start + e->data_off;
}
```

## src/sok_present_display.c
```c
/*
 * SPDX-License-Identifier: Apache-2.0
 *
 * PiZZa sokoban -- display present backend (CONFIG_SOKOBAN_PRESENT_DISPLAY).
 *
 * Pushes the renderer's 640x480 ARGB8888 backing at the Zephyr display
 * API. On rpi_zero_2w that is bcm2835_fb with a 640x480 virtual
 * framebuffer (640 * 4 = 2560 B/row, 64-byte aligned so the driver's
 * contiguous-DMA fast path engages); the VideoCore HVS scales to the
 * monitor's native mode -- the proven Doom / SDLPoP / Mini vMac path.
 */

#include <zephyr/kernel.h>
#include <zephyr/device.h>
#include <zephyr/drivers/display.h>
#include <zephyr/logging/log.h>

#include "sdl2shim.h"

LOG_MODULE_REGISTER(sok_present, CONFIG_SDL2SHIM_LOG_LEVEL);

#define SOK_W 640
#define SOK_H 480

static const struct device *display_dev;
static uint32_t backbuf[SOK_W * SOK_H];
static bool ready;

int s2s_present_init(int width, int height)
{
	if (width != SOK_W || height != SOK_H) {
		LOG_ERR("present: %dx%d requested, backend is fixed %dx%d",
			width, height, SOK_W, SOK_H);
		return -EINVAL;
	}

	display_dev = DEVICE_DT_GET(DT_CHOSEN(zephyr_display));
	if (!device_is_ready(display_dev)) {
		LOG_ERR("present: display device not ready -- HDMI not connected?");
		return -ENODEV;
	}

	struct display_capabilities caps;

	display_get_capabilities(display_dev, &caps);
	LOG_INF("present: display %ux%u (HVS virt) fmt=0x%x",
		caps.x_resolution, caps.y_resolution,
		(unsigned int)caps.current_pixel_format);

	if (caps.x_resolution != SOK_W || caps.y_resolution != SOK_H) {
		LOG_WRN("present: display reports %ux%u, expected %ux%u "
			"(check render-width/render-height in overlay)",
			caps.x_resolution, caps.y_resolution, SOK_W, SOK_H);
	}

	ready = true;
	return 0;
}

void s2s_present_frame(const void *argb_pixels, int pitch)
{
	if (!ready) {
		return;
	}

	const uint8_t *src_row = argb_pixels;
	uint32_t *dst = backbuf;

	for (int y = 0; y < SOK_H; y++) {
		const uint32_t *px = (const uint32_t *)src_row;

		for (int x = 0; x < SOK_W; x++) {
			*dst++ = 0xFF000000u | (px[x] & 0x00FFFFFFu);
		}
		src_row += pitch;
	}

	struct display_buffer_descriptor desc = {
		.buf_size = sizeof(backbuf),
		.width = SOK_W,
		.height = SOK_H,
		.pitch = SOK_W,
		.frame_incomplete = false,
	};

	int rc = display_write(display_dev, 0, 0, &desc, backbuf);

	if (rc != 0) {
		LOG_ERR("present: display_write rc=%d", rc);
	}
}
```

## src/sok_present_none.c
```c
/*
 * SPDX-License-Identifier: Apache-2.0
 *
 * PiZZa sokoban -- frame-dropping present backend
 * (CONFIG_SOKOBAN_PRESENT_NONE, link/bring-up).
 */

#include <zephyr/kernel.h>
#include <zephyr/logging/log.h>

#include "sdl2shim.h"

LOG_MODULE_REGISTER(sok_present, CONFIG_SDL2SHIM_LOG_LEVEL);

int s2s_present_init(int width, int height)
{
	LOG_INF("present: none backend (%dx%d frames dropped)", width, height);
	return 0;
}

void s2s_present_frame(const void *pixels, int pitch)
{
	ARG_UNUSED(pixels);
	ARG_UNUSED(pitch);
}
```

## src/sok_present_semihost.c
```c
/*
 * SPDX-License-Identifier: Apache-2.0
 *
 * PiZZa sokoban -- semihosting capture present backend
 * (CONFIG_SOKOBAN_PRESENT_SEMIHOST, qemu sim gates).
 *
 * Frames land on the host filesystem as binary PPM (P6) files. Frame 1
 * is always written; with CONFIG_SOKOBAN_CAPTURE_EVERY=N > 0 every Nth
 * frame is written too, so the scripted title -> level 1 -> movement
 * progression is captured across several files.
 */

#include <zephyr/kernel.h>
#include <zephyr/arch/common/semihost.h>
#include <zephyr/logging/log.h>
#include <stdio.h>

#include "sdl2shim.h"

LOG_MODULE_REGISTER(sok_present, CONFIG_SDL2SHIM_LOG_LEVEL);

static int fb_w;
static int fb_h;
static uint32_t frames;

int s2s_present_init(int width, int height)
{
	fb_w = width;
	fb_h = height;
	LOG_INF("present: semihost capture backend (%dx%d)", width, height);
	return 0;
}

void s2s_present_frame(const void *argb_pixels, int pitch)
{
	frames++;

	bool capture = (frames == 1);

	if (CONFIG_SOKOBAN_CAPTURE_EVERY > 0 &&
	    (frames % CONFIG_SOKOBAN_CAPTURE_EVERY) == 0) {
		capture = true;
	}
	if (!capture) {
		return;
	}

	char name[48];
	char header[32];

	snprintf(name, sizeof(name), "sokoban_frame_%06u.ppm", frames);

	long fd = semihost_open(name, SEMIHOST_OPEN_WB);

	if (fd < 0) {
		LOG_ERR("present: semihost_open(%s) = %ld", name, fd);
		return;
	}

	int hlen = snprintf(header, sizeof(header), "P6\n%d %d\n255\n", fb_w, fb_h);

	semihost_write(fd, header, hlen);

	/* Unpack ARGB -> RGB one row at a time. */
	static uint8_t rowbuf[640 * 3];
	const uint8_t *row = argb_pixels;

	for (int y = 0; y < fb_h; y++) {
		const uint32_t *px = (const uint32_t *)row;
		uint8_t *o = rowbuf;

		for (int x = 0; x < fb_w; x++) {
			uint32_t p = px[x];

			*o++ = (uint8_t)(p >> 16);  /* R */
			*o++ = (uint8_t)(p >> 8);   /* G */
			*o++ = (uint8_t)(p);        /* B */
		}
		semihost_write(fd, rowbuf, (long)fb_w * 3);
		row += pitch;
	}
	semihost_close(fd);
	LOG_INF("present: wrote %s", name);
}
```

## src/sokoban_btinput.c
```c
/*
 * SPDX-License-Identifier: Apache-2.0
 *
 * PiZZa sokoban -- Bluetooth HID input (CONFIG_BTINPUT).
 *
 * The whole BT stack lives in apps/lib/btinput (manager = bring-up +
 * connection policy on its own thread; SDL seam = events into the
 * sdl2shim queue App::Run already drains). This TU is only consumer
 * policy: remap the 8BitDo Micro's stock K-mode letters onto sokoban's
 * keys. Any real BT keyboard passes through unmapped -- HID usages are
 * SDL scancodes 1:1, so its actual O/M/R/U/arrow keys just work.
 */

#include <zephyr/kernel.h>

#include <SDL2/SDL.h>

#include "btinput.h"

/* 8BitDo Micro, K mode, stock map (same usage set the DOSBox port
 * confirmed). The four provisional usages (0x0e/0x0f/0x10/0x15 --
 * L2/R2/Plus/Minus/Star in some order) are pinned to keys sokoban
 * IGNORES on purpose: unmapped they'd pass through as their raw
 * letters k/l/m/r, and stray 'm' starts Microban / 'r' restarts the
 * level.
 */
static const struct btinput_seam_key pad_map[] = {
	{ 0x06, SDL_SCANCODE_UP },     /* d-pad Up    (C)             */
	{ 0x07, SDL_SCANCODE_DOWN },   /* d-pad Down  (D)             */
	{ 0x08, SDL_SCANCODE_LEFT },   /* d-pad Left  (E)             */
	{ 0x09, SDL_SCANCODE_RIGHT },  /* d-pad Right (F)             */
	{ 0x0a, SDL_SCANCODE_SPACE },  /* A (G) -> continue           */
	{ 0x0d, SDL_SCANCODE_U },      /* B (J) -> undo move          */
	{ 0x0b, SDL_SCANCODE_O },      /* X (H) -> start Original     */
	{ 0x0c, SDL_SCANCODE_M },      /* Y (I) -> start Microban     */
	{ 0x12, SDL_SCANCODE_R },      /* L (O) -> restart level      */
	{ 0x11, SDL_SCANCODE_P },      /* R (N) -> pause              */
	/* Home fires during the pad's power-off long-press, so it must NOT
	 * be ESCAPE: powering the pad off would quit the game (HW
	 * 2026-07-11). No pad button quits; ESC stays reachable from a
	 * real keyboard or `sok key esc`, and shim_main relaunches anyway.
	 */
	{ 0x16, SDL_SCANCODE_RETURN }, /* Home -> inert               */
	{ 0x0e, SDL_SCANCODE_RETURN }, /* provisional -> inert        */
	{ 0x0f, SDL_SCANCODE_RETURN }, /* provisional -> inert        */
	{ 0x10, SDL_SCANCODE_TAB },    /* provisional -> inert        */
	{ 0x15, SDL_SCANCODE_TAB },    /* provisional -> inert        */
};

void sokoban_btinput_start(void)
{
	btinput_seam_sdl_set_keymap(pad_map, ARRAY_SIZE(pad_map));
	btinput_seam_sdl_set_bounds(640, 480);
	btinput_seam_sdl_attach();
	btinput_manager_start();
}
```
